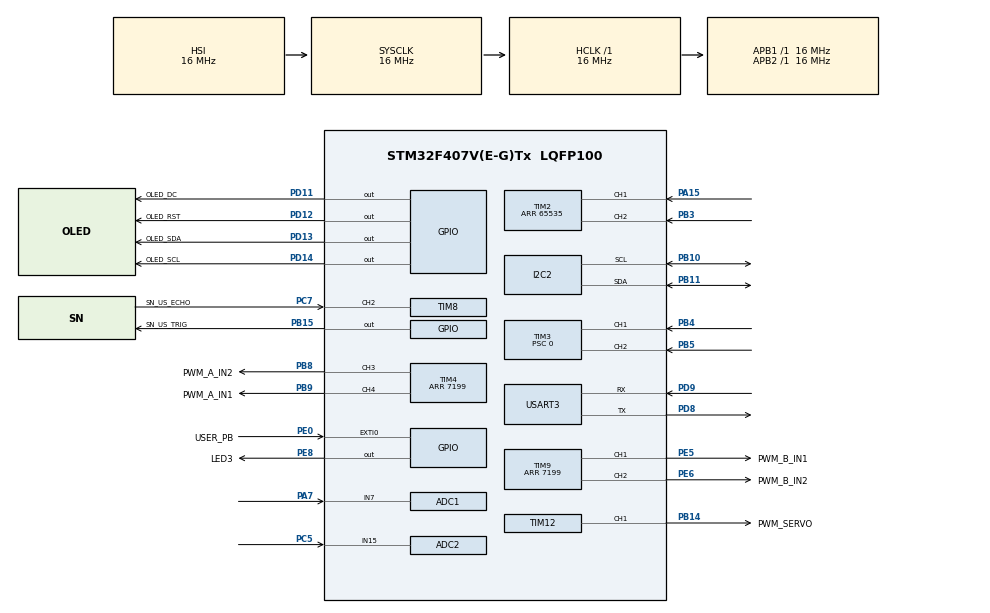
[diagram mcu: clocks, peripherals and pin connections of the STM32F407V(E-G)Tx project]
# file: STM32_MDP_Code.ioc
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ADC1.Channel-0\#ChannelRegularConversion=ADC_CHANNEL_7
ADC1.NbrOfConversion=1
ADC1.NbrOfConversionFlag=1
ADC1.Rank-0\#ChannelRegularConversion=1
ADC1.SamplingTime-0\#ChannelRegularConversion=ADC_SAMPLETIME_84CYCLES
ADC1.master=1
ADC2.Channel-1\#ChannelRegularConversion=ADC_CHANNEL_15
ADC2.NbrOfConversionFlag=1
ADC2.Rank-1\#ChannelRegularConversion=1
ADC2.SamplingTime-1\#ChannelRegularConversion=ADC_SAMPLETIME_84CYCLES
Dma.Request0=USART3_RX
Dma.Request1=USART3_TX
Dma.USART3_RX.0.Direction=DMA_PERIPH_TO_MEMORY
Dma.USART3_RX.0.FIFOMode=DMA_FIFOMODE_DISABLE
Dma.USART3_RX.0.Instance=DMA1_Stream1
Dma.USART3_RX.0.MemDataAlignment=DMA_MDATAALIGN_BYTE
Dma.USART3_RX.0.MemInc=DMA_MINC_ENABLE
Dma.USART3_RX.0.Mode=DMA_NORMAL
Dma.USART3_RX.0.PeriphDataAlignment=DMA_PDATAALIGN_BYTE
Dma.USART3_RX.0.PeriphInc=DMA_PINC_DISABLE
Dma.USART3_RX.0.Priority=DMA_PRIORITY_LOW
Dma.USART3_TX.1.Direction=DMA_MEMORY_TO_PERIPH
Dma.USART3_TX.1.FIFOMode=DMA_FIFOMODE_DISABLE
Dma.USART3_TX.1.Instance=DMA1_Stream3
Dma.USART3_TX.1.MemDataAlignment=DMA_MDATAALIGN_BYTE
Dma.USART3_TX.1.MemInc=DMA_MINC_ENABLE
Dma.USART3_TX.1.Mode=DMA_NORMAL
Dma.USART3_TX.1.PeriphDataAlignment=DMA_PDATAALIGN_BYTE
Dma.USART3_TX.1.PeriphInc=DMA_PINC_DISABLE
Dma.USART3_TX.1.Priority=DMA_PRIORITY_LOW
FREERTOS.Tasks01=defaultTask,24,128,StartDefaultTask,Default,NULL,Dynamic,NULL,NULL
Mcu.Family=STM32F4
Mcu.Name=STM32F407V(E-G)Tx
Mcu.Package=LQFP100
NVIC.DMA1_Stream1_IRQn=true\:5\:0\:false\:false\:true\:true\:false\:true\:true
NVIC.DMA1_Stream3_IRQn=true\:5\:0\:false\:false\:true\:true\:false\:true\:true
NVIC.EXTI0_IRQn=true\:5\:0\:false\:false\:true\:true\:true\:true\:true
NVIC.PriorityGroup=NVIC_PRIORITYGROUP_4
NVIC.TIM3_IRQn=true\:5\:0\:false\:false\:true\:true\:true\:true\:true
NVIC.TIM8_CC_IRQn=true\:5\:0\:false\:false\:true\:true\:true\:true\:true
NVIC.USART3_IRQn=true\:5\:0\:false\:false\:true\:true\:true\:true\:true
PA15.Signal=S_TIM2_CH1_ETR
PA7.Signal=ADCx_IN7
PB10.Mode=I2C
PB10.Signal=I2C2_SCL
PB11.Mode=I2C
PB11.Signal=I2C2_SDA
PB14.GPIO_Label=PWM_SERVO
PB14.Signal=S_TIM12_CH1
PB15.GPIO_Label=SN_US_TRIG
PB15.Signal=GPIO_Output
PB3.Signal=S_TIM2_CH2
PB4.Signal=S_TIM3_CH1
PB5.Signal=S_TIM3_CH2
PB8.GPIO_Label=PWM_A_IN2
PB8.Signal=S_TIM4_CH3
PB9.GPIO_Label=PWM_A_IN1
PB9.Signal=S_TIM4_CH4
PC5.Signal=ADCx_IN15
PC7.GPIO_Label=SN_US_ECHO
PC7.Signal=S_TIM8_CH2
PD11.GPIO_Label=OLED_DC
PD11.Signal=GPIO_Output
PD12.GPIO_Label=OLED_RST
PD12.Signal=GPIO_Output
PD13.GPIO_Label=OLED_SDA
PD13.Signal=GPIO_Output
PD14.GPIO_Label=OLED_SCL
PD14.Signal=GPIO_Output
PD8.Mode=Asynchronous
PD8.Signal=USART3_TX
PD9.GPIO_PuPd=GPIO_PULLDOWN
PD9.Mode=Asynchronous
PD9.Signal=USART3_RX
PE0.GPIO_Label=USER_PB
PE0.GPIO_ModeDefaultEXTI=GPIO_MODE_IT_FALLING
PE0.Signal=GPXTI0
PE5.GPIO_Label=PWM_B_IN1
PE5.Signal=S_TIM9_CH1
PE6.GPIO_Label=PWM_B_IN2
PE6.Signal=S_TIM9_CH2
PE8.GPIO_Label=LED3
PE8.Signal=GPIO_Output
ProjectManager.HeapSize=0x200
ProjectManager.StackSize=0x400
ProjectManager.TargetToolchain=STM32CubeIDE
RCC.AHBFreq_Value=16000000
RCC.APB1Freq_Value=16000000
RCC.APB2Freq_Value=16000000
RCC.CortexFreq_Value=16000000
RCC.HSE_VALUE=25000000
RCC.HSI_VALUE=16000000
RCC.LSE_VALUE=32768
RCC.SYSCLKFreq_VALUE=16000000
RCC.VCOOutputFreq_Value=192000000
SH.ADCx_IN15.0=ADC2_IN15,IN15
SH.ADCx_IN7.0=ADC1_IN7,IN7
SH.S_TIM12_CH1.0=TIM12_CH1,PWM Generation1 CH1
SH.S_TIM2_CH1_ETR.0=TIM2_CH1,Encoder_Interface
SH.S_TIM2_CH2.0=TIM2_CH2,Encoder_Interface
SH.S_TIM3_CH1.0=TIM3_CH1,Encoder_Interface
SH.S_TIM3_CH2.0=TIM3_CH2,Encoder_Interface
SH.S_TIM4_CH3.0=TIM4_CH3,PWM Generation3 CH3
SH.S_TIM4_CH4.0=TIM4_CH4,PWM Generation4 CH4
SH.S_TIM8_CH2.0=TIM8_CH2,Input_Capture2_from_TI2
SH.S_TIM9_CH1.0=TIM9_CH1,PWM Generation1 CH1
SH.S_TIM9_CH2.0=TIM9_CH2,PWM Generation2 CH2
TIM12.Channel-PWM\ Generation1\ CH1=TIM_CHANNEL_1
TIM12.OCPolarity_1=TIM_OCPOLARITY_HIGH
TIM12.Period=1000
TIM12.Prescaler=720
TIM2.EncoderMode=TIM_ENCODERMODE_TI12
TIM2.Period=65535
TIM3.EncoderMode=TIM_ENCODERMODE_TI12
TIM3.Prescaler=0
TIM4.Channel-PWM\ Generation3\ CH3=TIM_CHANNEL_3
TIM4.Channel-PWM\ Generation4\ CH4=TIM_CHANNEL_4
TIM4.OCPolarity_3=TIM_OCPOLARITY_LOW
TIM4.OCPolarity_4=TIM_OCPOLARITY_LOW
TIM4.Period=7199
TIM6.Prescaler=0
TIM8.Channel-Input_Capture2_from_TI2=TIM_CHANNEL_2
TIM8.ICPolarity_CH2=TIM_INPUTCHANNELPOLARITY_BOTHEDGE
TIM8.Prescaler=16-1
TIM9.Channel-PWM\ Generation1\ CH1=TIM_CHANNEL_1
TIM9.Channel-PWM\ Generation2\ CH2=TIM_CHANNEL_2
TIM9.OCPolarity_1=TIM_OCPOLARITY_LOW
TIM9.OCPolarity_2=TIM_OCPOLARITY_LOW
TIM9.Period=7199
USART3.VirtualMode=VM_ASYNC
VP_FREERTOS_VS_CMSIS_V2.Mode=CMSIS_V2
VP_TIM12_VS_ClockSourceINT.Mode=Internal
VP_TIM4_VS_ClockSourceINT.Mode=Internal
VP_TIM6_VS_ClockSourceINT.Mode=Enable_Timer
VP_TIM8_VS_ClockSourceINT.Mode=Internal
VP_TIM9_VS_ClockSourceINT.Mode=Internal
board=custom

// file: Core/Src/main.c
/* USER CODE BEGIN Header */
/**
  ******************************************************************************
  * @file           : main.c
  * @brief          : Main program body
  ******************************************************************************
  * @attention
  *
  * Copyright (c) 2025 STMicroelectronics.
  * All rights reserved.
  *
  * This software is licensed under terms that can be found in the LICENSE file
  * in the root directory of this software component.
  * If no LICENSE file comes with this software, it is provided AS-IS.
  *
  ******************************************************************************
  */
/* USER CODE END Header */
#include "main.h"
#include "cmsis_os.h"

/* USER CODE BEGIN Includes */
#include "oled.h"
#include "math.h"
/* USER CODE END Includes */

/* USER CODE BEGIN PD */
ICM20948 imu;
/* USER CODE END PD */

ADC_HandleTypeDef hadc1;
ADC_HandleTypeDef hadc2;

I2C_HandleTypeDef hi2c2;

TIM_HandleTypeDef htim2;
TIM_HandleTypeDef htim3;
TIM_HandleTypeDef htim4;
TIM_HandleTypeDef htim6;
TIM_HandleTypeDef htim8;
TIM_HandleTypeDef htim9;
TIM_HandleTypeDef htim12;

UART_HandleTypeDef huart3;
DMA_HandleTypeDef hdma_usart3_rx;
DMA_HandleTypeDef hdma_usart3_tx;

/* Definitions for defaultTask */
osThreadId_t defaultTaskHandle;
const osThreadAttr_t defaultTask_attributes = {
  .name = "defaultTask",
  .stack_size = 128 * 4,
  .priority = (osPriority_t) osPriorityNormal,
};

void SystemClock_Config(void);
static void MX_GPIO_Init(void);
static void MX_DMA_Init(void);
static void MX_TIM6_Init(void);
static void MX_TIM8_Init(void);
static void MX_TIM4_Init(void);
static void MX_TIM9_Init(void);
static void MX_TIM12_Init(void);
static void MX_I2C2_Init(void);
static void MX_USART3_UART_Init(void);
static void MX_TIM2_Init(void);
static void MX_TIM3_Init(void);
static void MX_ADC1_Init(void);
static void MX_ADC2_Init(void);
void StartDefaultTask(void *argument);

int main(void)
{

  /* MCU Configuration--------------------------------------------------------*/

  /* Reset of all peripherals, Initializes the Flash interface and the Systick. */
  HAL_Init();

  /* Configure the system clock */
  SystemClock_Config();

  /* Initialize all configured peripherals */
  MX_GPIO_Init();
  MX_DMA_Init();
  MX_TIM6_Init();
  MX_TIM8_Init();
  MX_TIM4_Init();
  MX_TIM9_Init();
  MX_TIM12_Init();
  MX_I2C2_Init();
  MX_USART3_UART_Init();
  MX_TIM2_Init();
  MX_TIM3_Init();
  MX_ADC1_Init();
  MX_ADC2_Init();
  /* USER CODE BEGIN 2 */
  initializeCPPconstructs();

  /* USER CODE END 2 */

  /* Init scheduler */
  osKernelInitialize();

  /* Create the thread(s) */
  /* creation of defaultTask */
  defaultTaskHandle = osThreadNew(StartDefaultTask, NULL, &defaultTask_attributes);

  /* Start scheduler */
  osKernelStart();

  /* We should never get here as control is now taken by the scheduler */
  /* Infinite loop */
  while (1) {

   	}
}

void SystemClock_Config(void)
{
  RCC_OscInitTypeDef RCC_OscInitStruct = {0};
  RCC_ClkInitTypeDef RCC_ClkInitStruct = {0};

  /** Configure the main internal regulator output voltage
  */
  __HAL_RCC_PWR_CLK_ENABLE();
  __HAL_PWR_VOLTAGESCALING_CONFIG(PWR_REGULATOR_VOLTAGE_SCALE1);

  /** Initializes the RCC Oscillators according to the specified parameters
  * in the RCC_OscInitTypeDef structure.
  */
  RCC_OscInitStruct.OscillatorType = RCC_OSCILLATORTYPE_HSI;
  RCC_OscInitStruct.HSIState = RCC_HSI_ON;
  RCC_OscInitStruct.HSICalibrationValue = RCC_HSICALIBRATION_DEFAULT;
  RCC_OscInitStruct.PLL.PLLState = RCC_PLL_NONE;
  if (HAL_RCC_OscConfig(&RCC_OscInitStruct) != HAL_OK)
  {
    Error_Handler();
  }

  /** Initializes the CPU, AHB and APB buses clocks
  */
  RCC_ClkInitStruct.ClockType = RCC_CLOCKTYPE_HCLK|RCC_CLOCKTYPE_SYSCLK
                              |RCC_CLOCKTYPE_PCLK1|RCC_CLOCKTYPE_PCLK2;
  RCC_ClkInitStruct.SYSCLKSource = RCC_SYSCLKSOURCE_HSI;
  RCC_ClkInitStruct.AHBCLKDivider = RCC_SYSCLK_DIV1;
  RCC_ClkInitStruct.APB1CLKDivider = RCC_HCLK_DIV1;
  RCC_ClkInitStruct.APB2CLKDivider = RCC_HCLK_DIV1;

  if (HAL_RCC_ClockConfig(&RCC_ClkInitStruct, FLASH_LATENCY_0) != HAL_OK)
  {
    Error_Handler();
  }
}

static void MX_ADC1_Init(void)
{

  ADC_ChannelConfTypeDef sConfig = {0};

  /** Configure the global features of the ADC (Clock, Resolution, Data Alignment and number of conversion)
  */
  hadc1.Instance = ADC1;
  hadc1.Init.ClockPrescaler = ADC_CLOCK_SYNC_PCLK_DIV2;
  hadc1.Init.Resolution = ADC_RESOLUTION_12B;
  hadc1.Init.ScanConvMode = DISABLE;
  hadc1.Init.ContinuousConvMode = DISABLE;
  hadc1.Init.DiscontinuousConvMode = DISABLE;
  hadc1.Init.ExternalTrigConvEdge = ADC_EXTERNALTRIGCONVEDGE_NONE;
  hadc1.Init.ExternalTrigConv = ADC_SOFTWARE_START;
  hadc1.Init.DataAlign = ADC_DATAALIGN_RIGHT;
  hadc1.Init.NbrOfConversion = 1;
  hadc1.Init.DMAContinuousRequests = DISABLE;
  hadc1.Init.EOCSelection = ADC_EOC_SINGLE_CONV;
  if (HAL_ADC_Init(&hadc1) != HAL_OK)
  {
    Error_Handler();
  }

  /** Configure for the selected ADC regular channel its corresponding rank in the sequencer and its sample time.
  */
  sConfig.Channel = ADC_CHANNEL_7;
  sConfig.Rank = 1;
  sConfig.SamplingTime = ADC_SAMPLETIME_84CYCLES;
  if (HAL_ADC_ConfigChannel(&hadc1, &sConfig) != HAL_OK)
  {
    Error_Handler();
  }

}

static void MX_ADC2_Init(void)
{

  ADC_ChannelConfTypeDef sConfig = {0};

  /** Configure the global features of the ADC (Clock, Resolution, Data Alignment and number of conversion)
  */
  hadc2.Instance = ADC2;
  hadc2.Init.ClockPrescaler = ADC_CLOCK_SYNC_PCLK_DIV2;
  hadc2.Init.Resolution = ADC_RESOLUTION_12B;
  hadc2.Init.ScanConvMode = DISABLE;
  hadc2.Init.ContinuousConvMode = DISABLE;
  hadc2.Init.DiscontinuousConvMode = DISABLE;
  hadc2.Init.ExternalTrigConvEdge = ADC_EXTERNALTRIGCONVEDGE_NONE;
  hadc2.Init.ExternalTrigConv = ADC_SOFTWARE_START;
  hadc2.Init.DataAlign = ADC_DATAALIGN_RIGHT;
  hadc2.Init.NbrOfConversion = 1;
  hadc2.Init.DMAContinuousRequests = DISABLE;
  hadc2.Init.EOCSelection = ADC_EOC_SINGLE_CONV;
  if (HAL_ADC_Init(&hadc2) != HAL_OK)
  {
    Error_Handler();
  }

  /** Configure for the selected ADC regular channel its corresponding rank in the sequencer and its sample time.
  */
  sConfig.Channel = ADC_CHANNEL_15;
  sConfig.Rank = 1;
  sConfig.SamplingTime = ADC_SAMPLETIME_84CYCLES;
  if (HAL_ADC_ConfigChannel(&hadc2, &sConfig) != HAL_OK)
  {
    Error_Handler();
  }

}

static void MX_I2C2_Init(void)
{

  hi2c2.Instance = I2C2;
  hi2c2.Init.ClockSpeed = 100000;
  hi2c2.Init.DutyCycle = I2C_DUTYCYCLE_2;
  hi2c2.Init.OwnAddress1 = 0;
  hi2c2.Init.AddressingMode = I2C_ADDRESSINGMODE_7BIT;
  hi2c2.Init.DualAddressMode = I2C_DUALADDRESS_DISABLE;
  hi2c2.Init.OwnAddress2 = 0;
  hi2c2.Init.GeneralCallMode = I2C_GENERALCALL_DISABLE;
  hi2c2.Init.NoStretchMode = I2C_NOSTRETCH_DISABLE;
  if (HAL_I2C_Init(&hi2c2) != HAL_OK)
  {
    Error_Handler();
  }

}

static void MX_TIM2_Init(void)
{

  TIM_Encoder_InitTypeDef sConfig = {0};
  TIM_MasterConfigTypeDef sMasterConfig = {0};

  htim2.Instance = TIM2;
  htim2.Init.Prescaler = 0;
  htim2.Init.CounterMode = TIM_COUNTERMODE_UP;
  htim2.Init.Period = 65535;
  htim2.Init.ClockDivision = TIM_CLOCKDIVISION_DIV1;
  htim2.Init.AutoReloadPreload = TIM_AUTORELOAD_PRELOAD_DISABLE;
  sConfig.EncoderMode = TIM_ENCODERMODE_TI12;
  sConfig.IC1Polarity = TIM_ICPOLARITY_RISING;
  sConfig.IC1Selection = TIM_ICSELECTION_DIRECTTI;
  sConfig.IC1Prescaler = TIM_ICPSC_DIV1;
  sConfig.IC1Filter = 0;
  sConfig.IC2Polarity = TIM_ICPOLARITY_RISING;
  sConfig.IC2Selection = TIM_ICSELECTION_DIRECTTI;
  sConfig.IC2Prescaler = TIM_ICPSC_DIV1;
  sConfig.IC2Filter = 0;
  if (HAL_TIM_Encoder_Init(&htim2, &sConfig) != HAL_OK)
  {
    Error_Handler();
  }
  sMasterConfig.MasterOutputTrigger = TIM_TRGO_RESET;
  sMasterConfig.MasterSlaveMode = TIM_MASTERSLAVEMODE_DISABLE;
  if (HAL_TIMEx_MasterConfigSynchronization(&htim2, &sMasterConfig) != HAL_OK)
  {
    Error_Handler();
  }

}

static void MX_TIM3_Init(void)
{

  TIM_Encoder_InitTypeDef sConfig = {0};
  TIM_MasterConfigTypeDef sMasterConfig = {0};

  htim3.Instance = TIM3;
  htim3.Init.Prescaler = 0;
  htim3.Init.CounterMode = TIM_COUNTERMODE_UP;
  htim3.Init.Period = 65535;
  htim3.Init.ClockDivision = TIM_CLOCKDIVISION_DIV1;
  htim3.Init.AutoReloadPreload = TIM_AUTORELOAD_PRELOAD_DISABLE;
  sConfig.EncoderMode = TIM_ENCODERMODE_TI12;
  sConfig.IC1Polarity = TIM_ICPOLARITY_RISING;
  sConfig.IC1Selection = TIM_ICSELECTION_DIRECTTI;
  sConfig.IC1Prescaler = TIM_ICPSC_DIV1;
  sConfig.IC1Filter = 0;
  sConfig.IC2Polarity = TIM_ICPOLARITY_RISING;
  sConfig.IC2Selection = TIM_ICSELECTION_DIRECTTI;
  sConfig.IC2Prescaler = TIM_ICPSC_DIV1;
  sConfig.IC2Filter = 0;
  if (HAL_TIM_Encoder_Init(&htim3, &sConfig) != HAL_OK)
  {
    Error_Handler();
  }
  sMasterConfig.MasterOutputTrigger = TIM_TRGO_RESET;
  sMasterConfig.MasterSlaveMode = TIM_MASTERSLAVEMODE_DISABLE;
  if (HAL_TIMEx_MasterConfigSynchronization(&htim3, &sMasterConfig) != HAL_OK)
  {
    Error_Handler();
  }

}

static void MX_TIM4_Init(void)
{

  TIM_ClockConfigTypeDef sClockSourceConfig = {0};
  TIM_MasterConfigTypeDef sMasterConfig = {0};
  TIM_OC_InitTypeDef sConfigOC = {0};

  htim4.Instance = TIM4;
  htim4.Init.Prescaler = 0;
  htim4.Init.CounterMode = TIM_COUNTERMODE_UP;
  htim4.Init.Period = 7199;
  htim4.Init.ClockDivision = TIM_CLOCKDIVISION_DIV1;
  htim4.Init.AutoReloadPreload = TIM_AUTORELOAD_PRELOAD_DISABLE;
  if (HAL_TIM_Base_Init(&htim4) != HAL_OK)
  {
    Error_Handler();
  }
  sClockSourceConfig.ClockSource = TIM_CLOCKSOURCE_INTERNAL;
  if (HAL_TIM_ConfigClockSource(&htim4, &sClockSourceConfig) != HAL_OK)
  {
    Error_Handler();
  }
  if (HAL_TIM_PWM_Init(&htim4) != HAL_OK)
  {
    Error_Handler();
  }
  sMasterConfig.MasterOutputTrigger = TIM_TRGO_RESET;
  sMasterConfig.MasterSlaveMode = TIM_MASTERSLAVEMODE_DISABLE;
  if (HAL_TIMEx_MasterConfigSynchronization(&htim4, &sMasterConfig) != HAL_OK)
  {
    Error_Handler();
  }
  sConfigOC.OCMode = TIM_OCMODE_PWM1;
  sConfigOC.Pulse = 0;
  sConfigOC.OCPolarity = TIM_OCPOLARITY_LOW;
  sConfigOC.OCFastMode = TIM_OCFAST_DISABLE;
  if (HAL_TIM_PWM_ConfigChannel(&htim4, &sConfigOC, TIM_CHANNEL_3) != HAL_OK)
  {
    Error_Handler();
  }
  if (HAL_TIM_PWM_ConfigChannel(&htim4, &sConfigOC, TIM_CHANNEL_4) != HAL_OK)
  {
    Error_Handler();
  }
  HAL_TIM_MspPostInit(&htim4);

}

static void MX_TIM6_Init(void)
{

  TIM_MasterConfigTypeDef sMasterConfig = {0};

  htim6.Instance = TIM6;
  htim6.Init.Prescaler = 0;
  htim6.Init.CounterMode = TIM_COUNTERMODE_UP;
  htim6.Init.Period = 65535;
  htim6.Init.AutoReloadPreload = TIM_AUTORELOAD_PRELOAD_DISABLE;
  if (HAL_TIM_Base_Init(&htim6) != HAL_OK)
  {
    Error_Handler();
  }
  sMasterConfig.MasterOutputTrigger = TIM_TRGO_RESET;
  sMasterConfig.MasterSlaveMode = TIM_MASTERSLAVEMODE_DISABLE;
  if (HAL_TIMEx_MasterConfigSynchronization(&htim6, &sMasterConfig) != HAL_OK)
  {
    Error_Handler();
  }

}

static void MX_TIM8_Init(void)
{

  TIM_ClockConfigTypeDef sClockSourceConfig = {0};
  TIM_MasterConfigTypeDef sMasterConfig = {0};
  TIM_IC_InitTypeDef sConfigIC = {0};

  htim8.Instance = TIM8;
  htim8.Init.Prescaler = 16-1;
  htim8.Init.CounterMode = TIM_COUNTERMODE_UP;
  htim8.Init.Period = 65535;
  htim8.Init.ClockDivision = TIM_CLOCKDIVISION_DIV1;
  htim8.Init.RepetitionCounter = 0;
  htim8.Init.AutoReloadPreload = TIM_AUTORELOAD_PRELOAD_DISABLE;
  if (HAL_TIM_Base_Init(&htim8) != HAL_OK)
  {
    Error_Handler();
  }
  sClockSourceConfig.ClockSource = TIM_CLOCKSOURCE_INTERNAL;
  if (HAL_TIM_ConfigClockSource(&htim8, &sClockSourceConfig) != HAL_OK)
  {
    Error_Handler();
  }
  if (HAL_TIM_IC_Init(&htim8) != HAL_OK)
  {
    Error_Handler();
  }
  sMasterConfig.MasterOutputTrigger = TIM_TRGO_RESET;
  sMasterConfig.MasterSlaveMode = TIM_MASTERSLAVEMODE_DISABLE;
  if (HAL_TIMEx_MasterConfigSynchronization(&htim8, &sMasterConfig) != HAL_OK)
  {
    Error_Handler();
  }
  sConfigIC.ICPolarity = TIM_INPUTCHANNELPOLARITY_BOTHEDGE;
  sConfigIC.ICSelection = TIM_ICSELECTION_DIRECTTI;
  sConfigIC.ICPrescaler = TIM_ICPSC_DIV1;
  sConfigIC.ICFilter = 0;
  if (HAL_TIM_IC_ConfigChannel(&htim8, &sConfigIC, TIM_CHANNEL_2) != HAL_OK)
  {
    Error_Handler();
  }

}

static void MX_TIM9_Init(void)
{

  TIM_ClockConfigTypeDef sClockSourceConfig = {0};
  TIM_OC_InitTypeDef sConfigOC = {0};

  htim9.Instance = TIM9;
  htim9.Init.Prescaler = 0;
  htim9.Init.CounterMode = TIM_COUNTERMODE_UP;
  htim9.Init.Period = 7199;
  htim9.Init.ClockDivision = TIM_CLOCKDIVISION_DIV1;
  htim9.Init.AutoReloadPreload = TIM_AUTORELOAD_PRELOAD_DISABLE;
  if (HAL_TIM_Base_Init(&htim9) != HAL_OK)
  {
    Error_Handler();
  }
  sClockSourceConfig.ClockSource = TIM_CLOCKSOURCE_INTERNAL;
  if (HAL_TIM_ConfigClockSource(&htim9, &sClockSourceConfig) != HAL_OK)
  {
    Error_Handler();
  }
  if (HAL_TIM_PWM_Init(&htim9) != HAL_OK)
  {
    Error_Handler();
  }
  sConfigOC.OCMode = TIM_OCMODE_PWM1;
  sConfigOC.Pulse = 0;
  sConfigOC.OCPolarity = TIM_OCPOLARITY_LOW;
  sConfigOC.OCFastMode = TIM_OCFAST_DISABLE;
  if (HAL_TIM_PWM_ConfigChannel(&htim9, &sConfigOC, TIM_CHANNEL_1) != HAL_OK)
  {
    Error_Handler();
  }
  if (HAL_TIM_PWM_ConfigChannel(&htim9, &sConfigOC, TIM_CHANNEL_2) != HAL_OK)
  {
    Error_Handler();
  }
  HAL_TIM_MspPostInit(&htim9);

}

static void MX_TIM12_Init(void)
{

  TIM_ClockConfigTypeDef sClockSourceConfig = {0};
  TIM_OC_InitTypeDef sConfigOC = {0};

  htim12.Instance = TIM12;
  htim12.Init.Prescaler = 720;
  htim12.Init.CounterMode = TIM_COUNTERMODE_UP;
  htim12.Init.Period = 1000;
  htim12.Init.ClockDivision = TIM_CLOCKDIVISION_DIV1;
  htim12.Init.AutoReloadPreload = TIM_AUTORELOAD_PRELOAD_DISABLE;
  if (HAL_TIM_Base_Init(&htim12) != HAL_OK)
  {
    Error_Handler();
  }
  sClockSourceConfig.ClockSource = TIM_CLOCKSOURCE_INTERNAL;
  if (HAL_TIM_ConfigClockSource(&htim12, &sClockSourceConfig) != HAL_OK)
  {
    Error_Handler();
  }
  if (HAL_TIM_PWM_Init(&htim12) != HAL_OK)
  {
    Error_Handler();
  }
  sConfigOC.OCMode = TIM_OCMODE_PWM1;
  sConfigOC.Pulse = 0;
  sConfigOC.OCPolarity = TIM_OCPOLARITY_HIGH;
  sConfigOC.OCFastMode = TIM_OCFAST_DISABLE;
  if (HAL_TIM_PWM_ConfigChannel(&htim12, &sConfigOC, TIM_CHANNEL_1) != HAL_OK)
  {
    Error_Handler();
  }
  HAL_TIM_MspPostInit(&htim12);

}

static void MX_USART3_UART_Init(void)
{

  huart3.Instance = USART3;
  huart3.Init.BaudRate = 115200;
  huart3.Init.WordLength = UART_WORDLENGTH_8B;
  huart3.Init.StopBits = UART_STOPBITS_1;
  huart3.Init.Parity = UART_PARITY_NONE;
  huart3.Init.Mode = UART_MODE_TX_RX;
  huart3.Init.HwFlowCtl = UART_HWCONTROL_NONE;
  huart3.Init.OverSampling = UART_OVERSAMPLING_16;
  if (HAL_UART_Init(&huart3) != HAL_OK)
  {
    Error_Handler();
  }

}

static void MX_DMA_Init(void)
{

  /* DMA controller clock enable */
  __HAL_RCC_DMA1_CLK_ENABLE();

  /* DMA interrupt init */
  /* DMA1_Stream1_IRQn interrupt configuration */
  HAL_NVIC_SetPriority(DMA1_Stream1_IRQn, 5, 0);
  HAL_NVIC_EnableIRQ(DMA1_Stream1_IRQn);
  /* DMA1_Stream3_IRQn interrupt configuration */
  HAL_NVIC_SetPriority(DMA1_Stream3_IRQn, 5, 0);
  HAL_NVIC_EnableIRQ(DMA1_Stream3_IRQn);

}

static void MX_GPIO_Init(void)
{
  GPIO_InitTypeDef GPIO_InitStruct = {0};

  /* GPIO Ports Clock Enable */
  __HAL_RCC_GPIOE_CLK_ENABLE();
  __HAL_RCC_GPIOA_CLK_ENABLE();
  __HAL_RCC_GPIOC_CLK_ENABLE();
  __HAL_RCC_GPIOB_CLK_ENABLE();
  __HAL_RCC_GPIOD_CLK_ENABLE();

  /*Configure GPIO pin Output Level */
  HAL_GPIO_WritePin(LED3_GPIO_Port, LED3_Pin, GPIO_PIN_RESET);

  /*Configure GPIO pin Output Level */
  HAL_GPIO_WritePin(SN_US_TRIG_GPIO_Port, SN_US_TRIG_Pin, GPIO_PIN_RESET);

  /*Configure GPIO pin Output Level */
  HAL_GPIO_WritePin(GPIOD, OLED_DC_Pin|OLED_RST_Pin|OLED_SDA_Pin|OLED_SCL_Pin, GPIO_PIN_RESET);

  /*Configure GPIO pin : LED3_Pin */
  GPIO_InitStruct.Pin = LED3_Pin;
  GPIO_InitStruct.Mode = GPIO_MODE_OUTPUT_PP;
  GPIO_InitStruct.Pull = GPIO_NOPULL;
  GPIO_InitStruct.Speed = GPIO_SPEED_FREQ_LOW;
  HAL_GPIO_Init(LED3_GPIO_Port, &GPIO_InitStruct);

  /*Configure GPIO pin : SN_US_TRIG_Pin */
  GPIO_InitStruct.Pin = SN_US_TRIG_Pin;
  GPIO_InitStruct.Mode = GPIO_MODE_OUTPUT_PP;
  GPIO_InitStruct.Pull = GPIO_NOPULL;
  GPIO_InitStruct.Speed = GPIO_SPEED_FREQ_LOW;
  HAL_GPIO_Init(SN_US_TRIG_GPIO_Port, &GPIO_InitStruct);

  /*Configure GPIO pins : OLED_DC_Pin OLED_RST_Pin OLED_SDA_Pin OLED_SCL_Pin */
  GPIO_InitStruct.Pin = OLED_DC_Pin|OLED_RST_Pin|OLED_SDA_Pin|OLED_SCL_Pin;
  GPIO_InitStruct.Mode = GPIO_MODE_OUTPUT_PP;
  GPIO_InitStruct.Pull = GPIO_NOPULL;
  GPIO_InitStruct.Speed = GPIO_SPEED_FREQ_LOW;
  HAL_GPIO_Init(GPIOD, &GPIO_InitStruct);

  /*Configure GPIO pin : USER_PB_Pin */
  GPIO_InitStruct.Pin = USER_PB_Pin;
  GPIO_InitStruct.Mode = GPIO_MODE_IT_FALLING;
  GPIO_InitStruct.Pull = GPIO_NOPULL;
  HAL_GPIO_Init(USER_PB_GPIO_Port, &GPIO_InitStruct);

  /* EXTI interrupt init*/
  HAL_NVIC_SetPriority(EXTI0_IRQn, 5, 0);
  HAL_NVIC_EnableIRQ(EXTI0_IRQn);

}

/* USER CODE BEGIN 4 */

void HAL_GPIO_EXTI_Callback( uint16_t GPIO_Pin ) {
     // see EXTI0_IRQHandler() in stm32f4xx_it.c for interrupt
	if (GPIO_Pin == USER_PB_Pin) {
//	        buttonPressed = 1;
	}
}

/* USER CODE END 4 */

void StartDefaultTask(void *argument)
{
  /* USER CODE BEGIN 5 */
  /* Infinite loop */
  for(;;)
  {
//	  HAL_GPIO_TogglePin(LED3_GPIO_Port, LED3_Pin); // debug
	  osDelay(50);
  }
  /* USER CODE END 5 */
}

void Error_Handler(void)
{
  __disable_irq();
  while (1)
  {
  }
}
